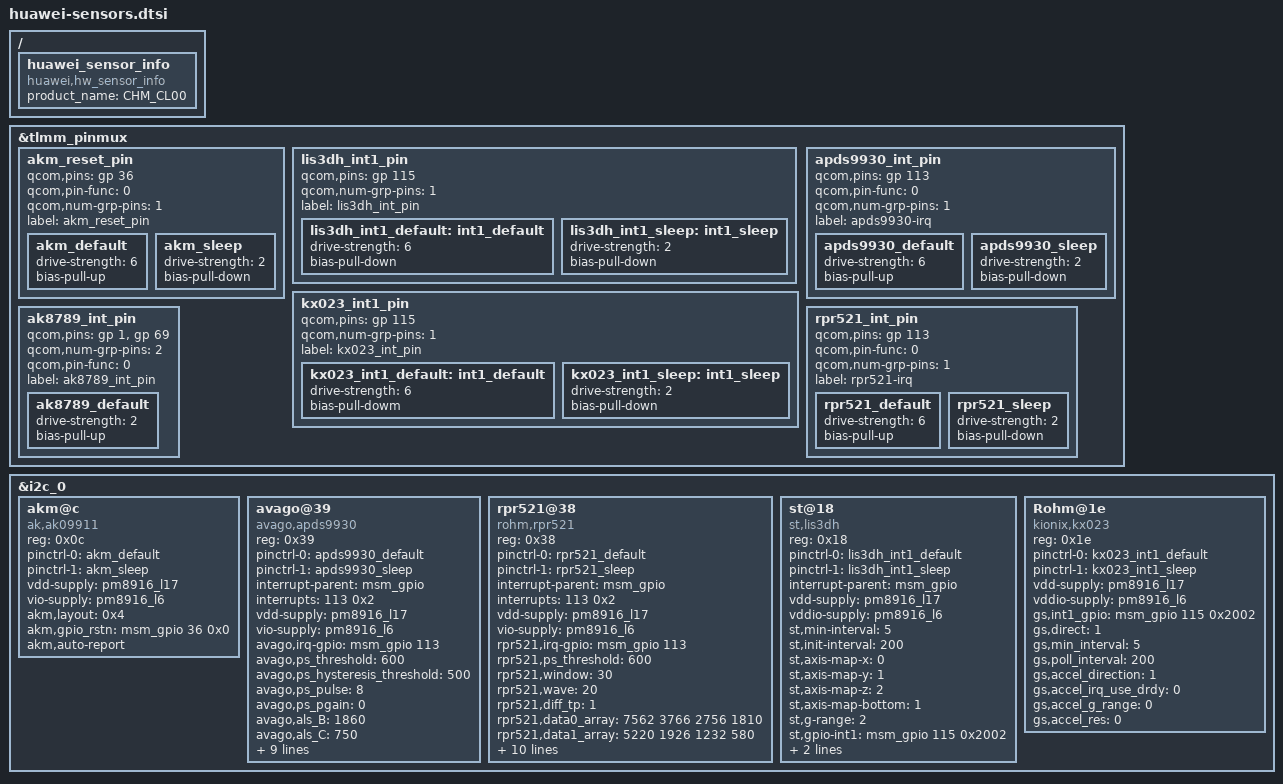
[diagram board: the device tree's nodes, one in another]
/* < DTS2014111203130 tanyanying 20141113 begin */
/* < DTS2014111811450 wanghang 20141118 begin */
/*use fromdos convert file format to linux*/
/* Copyright (c) 2013 The Linux Foundation. All rights reserved.
 *
 * This program is free software; you can redistribute it and/or modify
 * it under the terms of the GNU General Public License version 2 and
 * only version 2 as published by the Free Software Foundation.
 *
 * This program is distributed in the hope that it will be useful,
 * but WITHOUT ANY WARRANTY; without even the implied warranty of
 * MERCHANTABILITY or FITNESS FOR A PARTICULAR PURPOSE.  See the
 * GNU General Public License for more details.
 */
&tlmm_pinmux {
	akm_reset_pin {
		qcom,pins = <&gp 36>;
		qcom,pin-func = <0>;
		qcom,num-grp-pins = <1>;
		label = "akm_reset_pin";
		akm_default: akm_default {
			drive-strength = <6>;
			bias-pull-up;
		};
		akm_sleep: akm_sleep {
			drive-strength = <2>;
			bias-pull-down;
		};
	};

	lis3dh_int1_pin {
		qcom,pins = <&gp 115>;
		qcom,num-grp-pins = <1>;
		label = "lis3dh_int_pin";
		lis3dh_int1_default: int1_default {
			drive-strength = <6>;
			bias-pull-down;
		};
		lis3dh_int1_sleep: int1_sleep {
			drive-strength = <2>;
			bias-pull-down;
		};
	};

	kx023_int1_pin {
		qcom,pins = <&gp 115>;
		qcom,num-grp-pins = <1>;
		label = "kx023_int_pin";
		kx023_int1_default: int1_default {
			drive-strength = <6>;
			bias-pull-dowm;
		};
		kx023_int1_sleep: int1_sleep {
			drive-strength = <2>;
			bias-pull-down;
		};
	};
	apds9930_int_pin {
		qcom,pins = <&gp 113>;
		qcom,pin-func = <0>;
		qcom,num-grp-pins = <1>;
		label = "apds9930-irq";
		apds9930_default: apds9930_default {
			drive-strength = <6>;
			bias-pull-up;
		};
		apds9930_sleep: apds9930_sleep {
			drive-strength = <2>;
			bias-pull-down;
		};
	};
	/* DTS2014060502123 zhangyonggagn 20140606 begin  */
	ak8789_int_pin {
		qcom,pins = <&gp 1>, <&gp 69>;
		qcom,num-grp-pins = <2>;
		qcom,pin-func = <0>;
		label = "ak8789_int_pin";
		ak8789_default: ak8789_default {
			  drive-strength = <2>;
			  bias-pull-up;
		};
	};
	/* DTS2014060502123 zhangyonggagn 20140606 end  */
	rpr521_int_pin {
		qcom,pins = <&gp 113>;
		qcom,pin-func = <0>;
		qcom,num-grp-pins = <1>;
		label = "rpr521-irq";
		rpr521_default: rpr521_default {
			drive-strength = <6>;
			bias-pull-up;
		};
		rpr521_sleep: rpr521_sleep {
			drive-strength = <2>;
			bias-pull-down;
		};
	};
};

&i2c_0 { /* BLSP1 QUP2 */
	akm@c {
		compatible = "ak,ak09911";
		reg = <0x0c>;
		pinctrl-names = "default","sleep";
		pinctrl-0 = <&akm_default>;
		pinctrl-1 = <&akm_sleep>;
		vdd-supply = <&pm8916_l17>;
		vio-supply = <&pm8916_l6>;
		akm,layout = <0x4>;
		akm,gpio_rstn = <&msm_gpio 36 0x0>;
		akm,auto-report;
	};

	avago@39 {
		compatible = "avago,apds9930";
		reg = <0x39>;
		pinctrl-names = "default","sleep";
		pinctrl-0 = <&apds9930_default>;
		pinctrl-1 = <&apds9930_sleep>;
		interrupt-parent = <&msm_gpio>;
		interrupts = <113 0x2>;
		vdd-supply = <&pm8916_l17>;
		vio-supply = <&pm8916_l6>;
		avago,irq-gpio = <&msm_gpio 113 0x2>;
		avago,ps_threshold = <600>;
		avago,ps_hysteresis_threshold = <500>;
		avago,ps_pulse = <8>;
		avago,ps_pgain = <0>;
		/* < DTS2014061901549  wangcunyou 20140619 begin */
		/* < DTS2014121300349  zhangyonggang 20141213 begin */
		avago,als_B = <1860>;
		avago,als_C = <750>;
		avago,als_D = <1290>;
		/* DTS2014061901549 wangcunyou 20140619 end > */
		avago,ga_value = <48>;
	        /* BEGIN PN:DTS2014071604509,Added by z84020826, 2014/07/16*/
		avago,ga_a_value = <160>;
		avago,ga_c_value = <520>;
		avago,ga_d_value = <180>;
		avago,window = <75>;
		avago,wave = <55>;
		/* END PN:DTS2014071604509,Added by z84020826, 2014/07/16*/
		/* BEGIN PN:  DTS2014052808848,Added by z84020826, 2014/05/29*/
		avago,ga_e_value = <212>;
		avago,ga_f_value = <45>;
		/* < DTS2014121300349  zhangyonggang 20141213 end */
		/* END PN:  DTS2014052808848,Added by z84020826, 2014/05/29*/
	};
	rpr521@38 {
		compatible = "rohm,rpr521";
		reg = <0x38>;
		pinctrl-names = "default","sleep";
		pinctrl-0 = <&rpr521_default>;
		pinctrl-1 = <&rpr521_sleep>;
		interrupt-parent = <&msm_gpio>;
		interrupts = <113 0x2>;
		vdd-supply = <&pm8916_l17>;
		vio-supply = <&pm8916_l6>;
		rpr521,irq-gpio = <&msm_gpio 113 0x2>;
		rpr521,ps_threshold = <600>;
		/* < DTS2014092001161  zhangyonggang 20140920 begin */
		/* < DTS2014121800317  zhangyonggang 20141218 begin */
		rpr521,window = <30>;
		rpr521,wave = <20>;
		/* < DTS2015012000564 zhangyonggang 20150120 begin */
		rpr521,diff_tp = <1>;
		rpr521,data0_array = <7562 3766 2756 1810>;
		rpr521,data1_array = <5220 1926 1232 580>;
		rpr521,judge_array = <900 1350 2416 3100>;
		//ofilm
		rpr521,data0_array_of = <9033 4222 2776 1810>; 
		rpr521,data1_array_of = <6342 2140 1194 580>;   
		rpr521,judge_array_of = <900 1340 2333 3100>;
		//lensone
		rpr521,data0_array_le = <10843 9754 3779 1810>; 
		rpr521,data1_array_le = <6417 5571 1629 580>;   
		rpr521,judge_array_le = <1000 1520 2300 3100>;  
		//truly
		rpr521,data0_array_tr = <7562 3766 2756 1810>; 
		rpr521,data1_array_tr = <5220 1926 1232 580>;   
		rpr521,judge_array_tr = <900 1350 2416 3100>;  
		/* DTS2015012000564 zhangyonggang 20150120 end > */
		/* < DTS2014121800317  zhangyonggang 20141218 end */
		/* < DTS2014092001161  zhangyonggang 20140920 end > */
	};

	st@18 {
		compatible = "st,lis3dh";
		reg = <0x18>;
		/* < DTS2014052903301  yangzhonghua 20140529 begin */
		pinctrl-names = "lis3dh_default","lis3dh_sleep";
		pinctrl-0 = <&lis3dh_int1_default>;
		pinctrl-1 = <&lis3dh_int1_sleep>;
		/* DTS2014052903301  yangzhonghua 20140529 end > */
		interrupt-parent = <&msm_gpio>;
		vdd-supply = <&pm8916_l17>;
		vddio-supply = <&pm8916_l6>;
		st,min-interval = <5>;
		st,init-interval = <200>;
		st,axis-map-x = <0>;
		st,axis-map-y = <1>;
		st,axis-map-z = <2>;
		/*1 is bottom and others means top*/
                /* < DTS2014080402813  zhangyonggang 84020826 begin */
                st,axis-map-bottom=<1>;
                /* < DTS2014080402813  zhangyonggang 84020826 end */
		st,g-range = <2>;
		st,gpio-int1 = <&msm_gpio 115 0x2002>;
		/delete-property/st,negate-x;
		st,negate-z;
		st,negate-y;
	};
	Rohm@1e {
		compatible = "kionix,kx023";
		reg = <0x1e>;
		pinctrl-names = "kx023_default","kx023_sleep";
		pinctrl-0 = <&kx023_int1_default>;
		pinctrl-1 = <&kx023_int1_sleep>;
		vdd-supply = <&pm8916_l17>;
		vddio-supply = <&pm8916_l6>;
		gs,int1_gpio = <&msm_gpio 115 0x2002>;
		/*1 is bottom and others means top*/
                /* < DTS2014080402813  zhangyonggang 84020826 begin */
                gs,direct = <1>;
                /* < DTS2014080402813  zhangyonggang 84020826 end */
		gs,min_interval = <5>;
		gs,poll_interval = <200>;
		gs,accel_direction = <1>;
		gs,accel_irq_use_drdy = <0>;
		gs,accel_g_range = <0>;
		gs,accel_res = <0>;
	};
};

/* < DTS2015010509901 zhangyonggang 20150202 begin */
 / {
	huawei_sensor_info {
		compatible = "huawei,hw_sensor_info";
		product_name = "CHM_CL00";
	};
};
/* DTS2015010509901 zhangyonggang 20150202 end > */
/* DTS2014111811450 wanghang 20141118 end > */
/* DTS2014111203130 tanyanying 20141113 end > */

